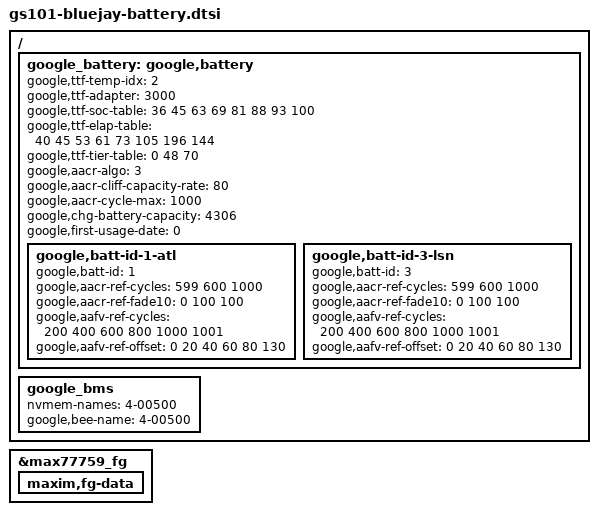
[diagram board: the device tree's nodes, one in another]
// SPDX-License-Identifier: GPL-2.0-only
/*
 * Battery device tree entries specific to bluejay
 *
 * Copyright 2021 Google,LLC
 *
 */

&google_battery {
	google,chg-battery-capacity = <4306>;
	google,first-usage-date = <0>;
};

&max77759_fg {
	maxim,fg-data {
		#include "gs101-bluejay-battery-data.dtsi"
	};
};

/ {
	fragment@battery {
		target-path = "/";
		__overlay__ {
			google_battery: google,battery {
				google,ttf-temp-idx= <2>;
				google,ttf-adapter = <3000>;
				google,ttf-soc-table =  <36 45 63 69 81 88  93  100>;
				google,ttf-elap-table = <40 45 53 61 73 105 196 144>;
				google,ttf-tier-table = <0 48 70>;

				/* 90% after 600 cycles, 80% after 1000 cycles */
				google,aacr-algo = <3>;
				google,aacr-cliff-capacity-rate = <80>;
				google,aacr-cycle-max = <1000>;

				google,batt-id-1-atl {
					google,batt-id = <1>;
					google,aacr-ref-cycles = <599 600 1000>;
					google,aacr-ref-fade10 = <  0 100  100>;
					google,aafv-ref-cycles = <200 400 600 800 1000 1001>;
					google,aafv-ref-offset = <  0  20  40  60   80  130>;
				};

				google,batt-id-3-lsn {
					google,batt-id = <3>;
					google,aacr-ref-cycles = <599 600 1000>;
					google,aacr-ref-fade10 = <  0 100  100>;
					google,aafv-ref-cycles = <200 400 600 800 1000 1001>;
					google,aafv-ref-offset = <  0  20  40  60   80  130>;
				};
			};
			google_bms {
				nvmem-names = "4-00500";
				/* pack eeprom is available only with P20+ batteries */
				google,bee-name = "4-00500";
			};
		};
	};
};
